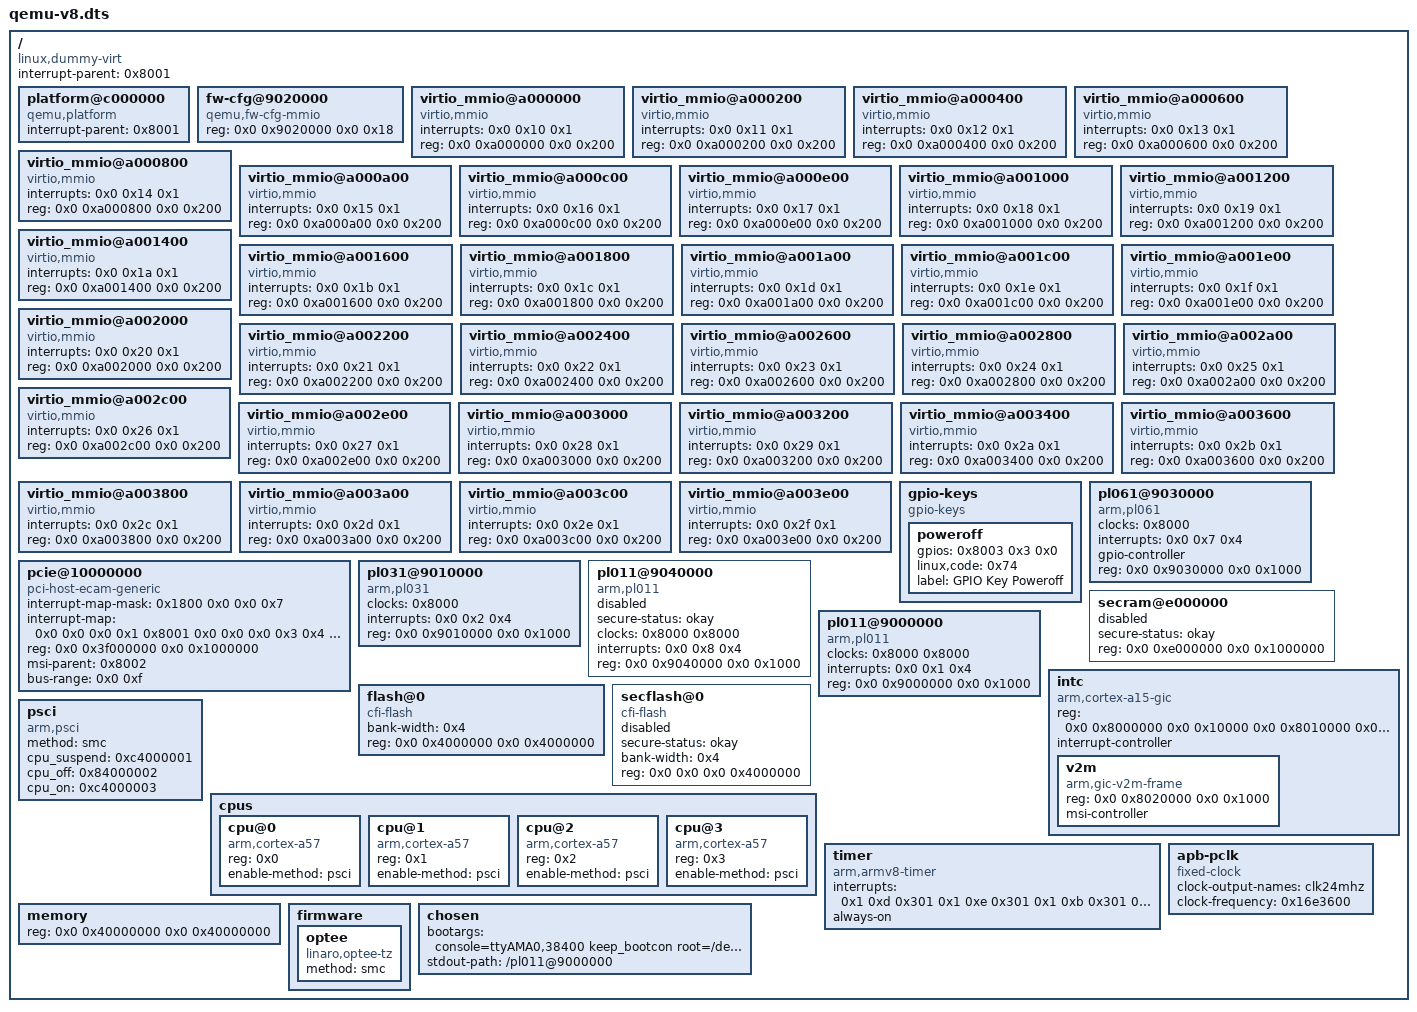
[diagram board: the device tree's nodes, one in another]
/dts-v1/;

/ {
	interrupt-parent = <0x8001>;
	#size-cells = <0x2>;
	#address-cells = <0x2>;
	compatible = "linux,dummy-virt";

	platform@c000000 {
		interrupt-parent = <0x8001>;
		ranges = <0x0 0x0 0xc000000 0x2000000>;
		#address-cells = <0x1>;
		#size-cells = <0x1>;
		compatible = "qemu,platform", "simple-bus";
	};

	fw-cfg@9020000 {
		reg = <0x0 0x9020000 0x0 0x18>;
		compatible = "qemu,fw-cfg-mmio";
	};

	virtio_mmio@a000000 {
		interrupts = <0x0 0x10 0x1>;
		reg = <0x0 0xa000000 0x0 0x200>;
		compatible = "virtio,mmio";
	};

	virtio_mmio@a000200 {
		interrupts = <0x0 0x11 0x1>;
		reg = <0x0 0xa000200 0x0 0x200>;
		compatible = "virtio,mmio";
	};

	virtio_mmio@a000400 {
		interrupts = <0x0 0x12 0x1>;
		reg = <0x0 0xa000400 0x0 0x200>;
		compatible = "virtio,mmio";
	};

	virtio_mmio@a000600 {
		interrupts = <0x0 0x13 0x1>;
		reg = <0x0 0xa000600 0x0 0x200>;
		compatible = "virtio,mmio";
	};

	virtio_mmio@a000800 {
		interrupts = <0x0 0x14 0x1>;
		reg = <0x0 0xa000800 0x0 0x200>;
		compatible = "virtio,mmio";
	};

	virtio_mmio@a000a00 {
		interrupts = <0x0 0x15 0x1>;
		reg = <0x0 0xa000a00 0x0 0x200>;
		compatible = "virtio,mmio";
	};

	virtio_mmio@a000c00 {
		interrupts = <0x0 0x16 0x1>;
		reg = <0x0 0xa000c00 0x0 0x200>;
		compatible = "virtio,mmio";
	};

	virtio_mmio@a000e00 {
		interrupts = <0x0 0x17 0x1>;
		reg = <0x0 0xa000e00 0x0 0x200>;
		compatible = "virtio,mmio";
	};

	virtio_mmio@a001000 {
		interrupts = <0x0 0x18 0x1>;
		reg = <0x0 0xa001000 0x0 0x200>;
		compatible = "virtio,mmio";
	};

	virtio_mmio@a001200 {
		interrupts = <0x0 0x19 0x1>;
		reg = <0x0 0xa001200 0x0 0x200>;
		compatible = "virtio,mmio";
	};

	virtio_mmio@a001400 {
		interrupts = <0x0 0x1a 0x1>;
		reg = <0x0 0xa001400 0x0 0x200>;
		compatible = "virtio,mmio";
	};

	virtio_mmio@a001600 {
		interrupts = <0x0 0x1b 0x1>;
		reg = <0x0 0xa001600 0x0 0x200>;
		compatible = "virtio,mmio";
	};

	virtio_mmio@a001800 {
		interrupts = <0x0 0x1c 0x1>;
		reg = <0x0 0xa001800 0x0 0x200>;
		compatible = "virtio,mmio";
	};

	virtio_mmio@a001a00 {
		interrupts = <0x0 0x1d 0x1>;
		reg = <0x0 0xa001a00 0x0 0x200>;
		compatible = "virtio,mmio";
	};

	virtio_mmio@a001c00 {
		interrupts = <0x0 0x1e 0x1>;
		reg = <0x0 0xa001c00 0x0 0x200>;
		compatible = "virtio,mmio";
	};

	virtio_mmio@a001e00 {
		interrupts = <0x0 0x1f 0x1>;
		reg = <0x0 0xa001e00 0x0 0x200>;
		compatible = "virtio,mmio";
	};

	virtio_mmio@a002000 {
		interrupts = <0x0 0x20 0x1>;
		reg = <0x0 0xa002000 0x0 0x200>;
		compatible = "virtio,mmio";
	};

	virtio_mmio@a002200 {
		interrupts = <0x0 0x21 0x1>;
		reg = <0x0 0xa002200 0x0 0x200>;
		compatible = "virtio,mmio";
	};

	virtio_mmio@a002400 {
		interrupts = <0x0 0x22 0x1>;
		reg = <0x0 0xa002400 0x0 0x200>;
		compatible = "virtio,mmio";
	};

	virtio_mmio@a002600 {
		interrupts = <0x0 0x23 0x1>;
		reg = <0x0 0xa002600 0x0 0x200>;
		compatible = "virtio,mmio";
	};

	virtio_mmio@a002800 {
		interrupts = <0x0 0x24 0x1>;
		reg = <0x0 0xa002800 0x0 0x200>;
		compatible = "virtio,mmio";
	};

	virtio_mmio@a002a00 {
		interrupts = <0x0 0x25 0x1>;
		reg = <0x0 0xa002a00 0x0 0x200>;
		compatible = "virtio,mmio";
	};

	virtio_mmio@a002c00 {
		interrupts = <0x0 0x26 0x1>;
		reg = <0x0 0xa002c00 0x0 0x200>;
		compatible = "virtio,mmio";
	};

	virtio_mmio@a002e00 {
		interrupts = <0x0 0x27 0x1>;
		reg = <0x0 0xa002e00 0x0 0x200>;
		compatible = "virtio,mmio";
	};

	virtio_mmio@a003000 {
		interrupts = <0x0 0x28 0x1>;
		reg = <0x0 0xa003000 0x0 0x200>;
		compatible = "virtio,mmio";
	};

	virtio_mmio@a003200 {
		interrupts = <0x0 0x29 0x1>;
		reg = <0x0 0xa003200 0x0 0x200>;
		compatible = "virtio,mmio";
	};

	virtio_mmio@a003400 {
		interrupts = <0x0 0x2a 0x1>;
		reg = <0x0 0xa003400 0x0 0x200>;
		compatible = "virtio,mmio";
	};

	virtio_mmio@a003600 {
		interrupts = <0x0 0x2b 0x1>;
		reg = <0x0 0xa003600 0x0 0x200>;
		compatible = "virtio,mmio";
	};

	virtio_mmio@a003800 {
		interrupts = <0x0 0x2c 0x1>;
		reg = <0x0 0xa003800 0x0 0x200>;
		compatible = "virtio,mmio";
	};

	virtio_mmio@a003a00 {
		interrupts = <0x0 0x2d 0x1>;
		reg = <0x0 0xa003a00 0x0 0x200>;
		compatible = "virtio,mmio";
	};

	virtio_mmio@a003c00 {
		interrupts = <0x0 0x2e 0x1>;
		reg = <0x0 0xa003c00 0x0 0x200>;
		compatible = "virtio,mmio";
	};

	virtio_mmio@a003e00 {
		interrupts = <0x0 0x2f 0x1>;
		reg = <0x0 0xa003e00 0x0 0x200>;
		compatible = "virtio,mmio";
	};

	gpio-keys {
		#address-cells = <0x1>;
		#size-cells = <0x0>;
		compatible = "gpio-keys";

		poweroff {
			gpios = <0x8003 0x3 0x0>;
			linux,code = <0x74>;
			label = "GPIO Key Poweroff";
		};
	};

	pl061@9030000 {
		phandle = <0x8003>;
		clock-names = "apb_pclk";
		clocks = <0x8000>;
		interrupts = <0x0 0x7 0x4>;
		gpio-controller;
		#gpio-cells = <0x2>;
		compatible = "arm,pl061", "arm,primecell";
		reg = <0x0 0x9030000 0x0 0x1000>;
	};

	pcie@10000000 {
		interrupt-map-mask = <0x1800 0x0 0x0 0x7>;
		interrupt-map = <0x0 0x0 0x0 0x1 0x8001 0x0 0x0 0x0 0x3 0x4 0x0 0x0 0x0 0x2 0x8001 0x0 0x0 0x0 0x4 0x4 0x0 0x0 0x0 0x3 0x8001 0x0 0x0 0x0 0x5 0x4 0x0 0x0 0x0 0x4 0x8001 0x0 0x0 0x0 0x6 0x4 0x800 0x0 0x0 0x1 0x8001 0x0 0x0 0x0 0x4 0x4 0x800 0x0 0x0 0x2 0x8001 0x0 0x0 0x0 0x5 0x4 0x800 0x0 0x0 0x3 0x8001 0x0 0x0 0x0 0x6 0x4 0x800 0x0 0x0 0x4 0x8001 0x0 0x0 0x0 0x3 0x4 0x1000 0x0 0x0 0x1 0x8001 0x0 0x0 0x0 0x5 0x4 0x1000 0x0 0x0 0x2 0x8001 0x0 0x0 0x0 0x6 0x4 0x1000 0x0 0x0 0x3 0x8001 0x0 0x0 0x0 0x3 0x4 0x1000 0x0 0x0 0x4 0x8001 0x0 0x0 0x0 0x4 0x4 0x1800 0x0 0x0 0x1 0x8001 0x0 0x0 0x0 0x6 0x4 0x1800 0x0 0x0 0x2 0x8001 0x0 0x0 0x0 0x3 0x4 0x1800 0x0 0x0 0x3 0x8001 0x0 0x0 0x0 0x4 0x4 0x1800 0x0 0x0 0x4 0x8001 0x0 0x0 0x0 0x5 0x4>;
		#interrupt-cells = <0x1>;
		ranges = <0x1000000 0x0 0x0 0x0 0x3eff0000 0x0 0x10000 0x2000000 0x0 0x10000000 0x0 0x10000000 0x0 0x2eff0000 0x3000000 0x80 0x0 0x80 0x0 0x80 0x0>;
		reg = <0x0 0x3f000000 0x0 0x1000000>;
		msi-parent = <0x8002>;
		bus-range = <0x0 0xf>;
		#size-cells = <0x2>;
		#address-cells = <0x3>;
		device_type = "pci";
		compatible = "pci-host-ecam-generic";
	};

	pl031@9010000 {
		clock-names = "apb_pclk";
		clocks = <0x8000>;
		interrupts = <0x0 0x2 0x4>;
		reg = <0x0 0x9010000 0x0 0x1000>;
		compatible = "arm,pl031", "arm,primecell";
	};

	pl011@9040000 {
		secure-status = "okay";
		status = "disabled";
		clock-names = "uartclk", "apb_pclk";
		clocks = <0x8000 0x8000>;
		interrupts = <0x0 0x8 0x4>;
		reg = <0x0 0x9040000 0x0 0x1000>;
		compatible = "arm,pl011", "arm,primecell";
	};

	secram@e000000 {
		secure-status = "okay";
		status = "disabled";
		reg = <0x0 0xe000000 0x0 0x1000000>;
		device_type = "memory";
	};

	pl011@9000000 {
		clock-names = "uartclk", "apb_pclk";
		clocks = <0x8000 0x8000>;
		interrupts = <0x0 0x1 0x4>;
		reg = <0x0 0x9000000 0x0 0x1000>;
		compatible = "arm,pl011", "arm,primecell";
	};

	intc {
		phandle = <0x8001>;
		reg = <0x0 0x8000000 0x0 0x10000 0x0 0x8010000 0x0 0x10000>;
		compatible = "arm,cortex-a15-gic";
		ranges;
		#size-cells = <0x2>;
		#address-cells = <0x2>;
		interrupt-controller;
		#interrupt-cells = <0x3>;

		v2m {
			phandle = <0x8002>;
			reg = <0x0 0x8020000 0x0 0x1000>;
			msi-controller;
			compatible = "arm,gic-v2m-frame";
		};
	};

	flash@0 {
		bank-width = <0x4>;
		reg = <0x0 0x4000000 0x0 0x4000000>;
		compatible = "cfi-flash";
	};

	secflash@0 {
		secure-status = "okay";
		status = "disabled";
		bank-width = <0x4>;
		reg = <0x0 0x0 0x0 0x4000000>;
		compatible = "cfi-flash";
	};

	psci {
		compatible = "arm,psci";
		method = "smc";
		cpu_suspend = <0xc4000001>;
		cpu_off = <0x84000002>;
		cpu_on = <0xc4000003>;
	};

	cpus {
		#size-cells = <0x0>;
		#address-cells = <0x1>;

		cpu@0 {
			reg = <0x0>;
			compatible = "arm,cortex-a57";
			device_type = "cpu";
			enable-method = "psci";
		};

		cpu@1 {
			reg = <0x1>;
			compatible = "arm,cortex-a57";
			device_type = "cpu";
			enable-method = "psci";
		};

		cpu@2 {
			reg = <0x2>;
			compatible = "arm,cortex-a57";
			device_type = "cpu";
			enable-method = "psci";
		};

		cpu@3 {
			reg = <0x3>;
			compatible = "arm,cortex-a57";
			device_type = "cpu";
			enable-method = "psci";
		};
	};

	timer {
		interrupts = <0x1 0xd 0x301 0x1 0xe 0x301 0x1 0xb 0x301 0x1 0xa 0x301>;
		always-on;
		compatible = "arm,armv8-timer", "arm,armv7-timer";
	};

	apb-pclk {
		phandle = <0x8000>;
		clock-output-names = "clk24mhz";
		clock-frequency = <0x16e3600>;
		#clock-cells = <0x0>;
		compatible = "fixed-clock";
	};

	memory {
		reg = <0x0 0x40000000 0x0 0x40000000>;
		device_type = "memory";
	};

	firmware {
		optee {
			compatible = "linaro,optee-tz";
			method = "smc";
		};
	};

	chosen {
		bootargs = "console=ttyAMA0,38400 keep_bootcon root=/dev/vda2";
		stdout-path = "/pl011@9000000";
	};
};
